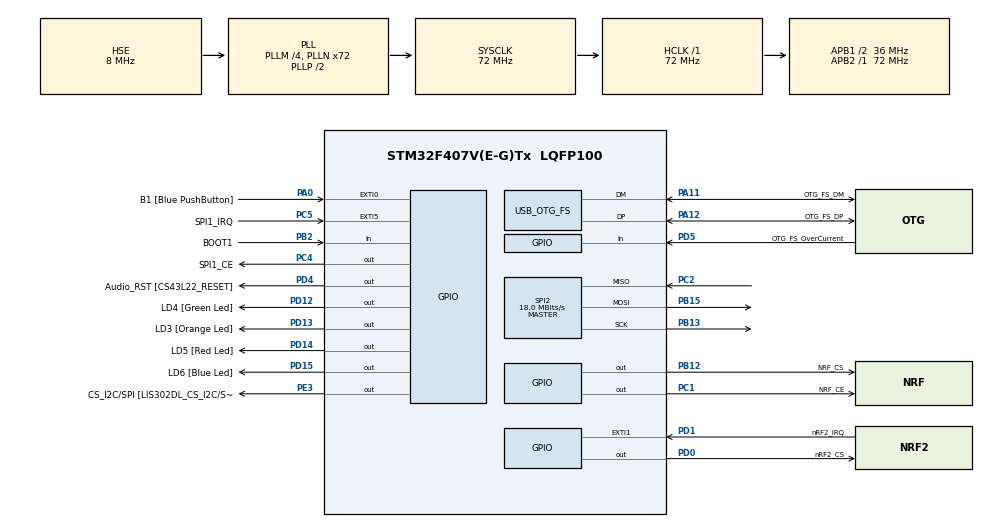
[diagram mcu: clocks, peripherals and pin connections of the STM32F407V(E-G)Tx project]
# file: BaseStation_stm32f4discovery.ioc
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FREERTOS.Tasks01=communicationTa,0,1024,communicationTask,As weak,NULL,Dynamic,NULL,NULL
Mcu.Family=STM32F4
Mcu.Name=STM32F407V(E-G)Tx
Mcu.Package=LQFP100
NVIC.OTG_FS_IRQn=true\:5\:0\:false\:false\:true\:true\:true\:true
NVIC.PriorityGroup=NVIC_PRIORITYGROUP_4
NVIC.TIM8_TRG_COM_TIM14_IRQn=true\:0\:0\:false\:false\:true\:false\:true\:true
NVIC.TimeBase=TIM8_TRG_COM_TIM14_IRQn
NVIC.TimeBaseIP=TIM14
PA0-WKUP.GPIO_Label=B1 [Blue PushButton]
PA0-WKUP.GPIO_ModeDefaultEXTI=GPIO_MODE_EVT_RISING
PA0-WKUP.GPIO_PuPd=GPIO_NOPULL
PA0-WKUP.Signal=GPXTI0
PA10.GPIO_Label=OTG_FS_ID
PA10.GPIO_Mode=GPIO_MODE_AF_PP
PA10.GPIO_PuPd=GPIO_NOPULL
PA10.GPIO_Speed=GPIO_SPEED_FREQ_LOW
PA10.Signal=USB_OTG_FS_ID
PA11.GPIO_Label=OTG_FS_DM
PA11.GPIO_Mode=GPIO_MODE_AF_PP
PA11.GPIO_PuPd=GPIO_NOPULL
PA11.GPIO_Speed=GPIO_SPEED_FREQ_LOW
PA11.Mode=Device_Only
PA11.Signal=USB_OTG_FS_DM
PA12.GPIO_Label=OTG_FS_DP
PA12.GPIO_Mode=GPIO_MODE_AF_PP
PA12.GPIO_PuPd=GPIO_NOPULL
PA12.GPIO_Speed=GPIO_SPEED_FREQ_LOW
PA12.Mode=Device_Only
PA12.Signal=USB_OTG_FS_DP
PA13.GPIO_Label=SWDIO
PA13.Signal=SYS_JTMS-SWDIO
PA14.GPIO_Label=SWCLK
PA14.Signal=SYS_JTCK-SWCLK
PA9.GPIO_Label=VBUS_FS
PA9.GPIO_Mode=GPIO_MODE_INPUT
PA9.GPIO_PuPd=GPIO_NOPULL
PA9.Signal=USB_OTG_FS_VBUS
PB12.GPIO_Label=NRF_CS
PB12.Signal=GPIO_Output
PB13.Mode=Full_Duplex_Master
PB13.Signal=SPI2_SCK
PB15.Mode=Full_Duplex_Master
PB15.Signal=SPI2_MOSI
PB2.GPIO_Label=BOOT1
PB2.GPIO_Mode=GPIO_MODE_INPUT
PB2.GPIO_PuPd=GPIO_NOPULL
PB2.Signal=GPIO_Input
PB3.GPIO_Label=SWO
PB3.Signal=SYS_JTDO-SWO
PC1.GPIO_Label=NRF_CE
PC1.Signal=GPIO_Output
PC14-OSC32_IN.Signal=RCC_OSC32_IN
PC15-OSC32_OUT.GPIO_Label=PC15-OSC32_OUT
PC15-OSC32_OUT.Signal=RCC_OSC32_OUT
PC2.Mode=Full_Duplex_Master
PC2.Signal=SPI2_MISO
PC4.GPIO_Label=SPI1_CE
PC4.Signal=GPIO_Output
PC5.GPIO_Label=SPI1_IRQ
PC5.Signal=GPXTI5
PD0.GPIO_Label=nRF2_CS
PD0.Signal=GPIO_Output
PD1.GPIO_Label=nRF2_IRQ
PD1.Signal=GPXTI1
PD12.GPIO_Label=LD4 [Green Led]
PD12.GPIO_PuPd=GPIO_NOPULL
PD12.GPIO_Speed=GPIO_SPEED_FREQ_LOW
PD12.Signal=GPIO_Output
PD13.GPIO_Label=LD3 [Orange Led]
PD13.GPIO_PuPd=GPIO_NOPULL
PD13.GPIO_Speed=GPIO_SPEED_FREQ_LOW
PD13.Signal=GPIO_Output
PD14.GPIO_Label=LD5 [Red Led]
PD14.GPIO_PuPd=GPIO_NOPULL
PD14.GPIO_Speed=GPIO_SPEED_FREQ_LOW
PD14.Signal=GPIO_Output
PD15.GPIO_Label=LD6 [Blue Led]
PD15.GPIO_PuPd=GPIO_NOPULL
PD15.GPIO_Speed=GPIO_SPEED_FREQ_LOW
PD15.Signal=GPIO_Output
PD4.GPIO_Label=Audio_RST [CS43L22_RESET]
PD4.GPIO_PuPd=GPIO_NOPULL
PD4.GPIO_Speed=GPIO_SPEED_FREQ_LOW
PD4.Signal=GPIO_Output
PD5.GPIO_Label=OTG_FS_OverCurrent
PD5.GPIO_Mode=GPIO_MODE_INPUT
PD5.GPIO_PuPd=GPIO_NOPULL
PD5.Signal=GPIO_Input
PE3.GPIO_Label=CS_I2C/SPI [LIS302DL_CS_I2C/SPI]
PE3.GPIO_PuPd=GPIO_NOPULL
PE3.GPIO_Speed=GPIO_SPEED_FREQ_LOW
PE3.Signal=GPIO_Output
PH0-OSC_IN.GPIO_Label=PH0-OSC_IN
PH0-OSC_IN.Mode=HSE-External-Oscillator
PH0-OSC_IN.Signal=RCC_OSC_IN
PH1-OSC_OUT.GPIO_Label=PH1-OSC_OUT
PH1-OSC_OUT.Mode=HSE-External-Oscillator
PH1-OSC_OUT.Signal=RCC_OSC_OUT
ProjectManager.HeapSize=0x200
ProjectManager.StackSize=0x400
ProjectManager.TargetToolchain=SW4STM32
RCC.48MHZClocksFreq_Value=48000000
RCC.AHBFreq_Value=72000000
RCC.APB1CLKDivider=RCC_HCLK_DIV2
RCC.APB1Freq_Value=36000000
RCC.APB1TimFreq_Value=72000000
RCC.APB2Freq_Value=72000000
RCC.APB2TimFreq_Value=72000000
RCC.CortexFreq_Value=72000000
RCC.HCLKFreq_Value=72000000
RCC.HSE_VALUE=8000000
RCC.HSI_VALUE=16000000
RCC.LSE_VALUE=32768
RCC.PLLM=4
RCC.PLLN=72
RCC.PLLQ=3
RCC.SYSCLKFreq_VALUE=72000000
RCC.SYSCLKSource=RCC_SYSCLKSOURCE_PLLCLK
RCC.VCOOutputFreq_Value=144000000
SPI2.CalculateBaudRate=18.0 MBits/s
SPI2.Direction=SPI_DIRECTION_2LINES
SPI2.Mode=SPI_MODE_MASTER
SPI2.VirtualType=VM_MASTER
USB_DEVICE.CLASS_NAME-CDC_FS=CDC
USB_DEVICE.CLASS_NAME_FS=CDC
USB_DEVICE.USBD_HandleTypeDef-CDC_FS=hUsbDeviceFS
USB_DEVICE.VirtualMode-CDC_FS=Cdc
USB_DEVICE.VirtualModeFS=Cdc_FS
USB_DEVICE.hUsbDevice-CDC_FS=hDeviceDuSmolt
USB_OTG_FS.VirtualMode=Device_Only
VP_FREERTOS_VS_CMSIS_V1.Mode=CMSIS_V1
VP_SYS_VS_tim14.Mode=TIM14
VP_USB_DEVICE_VS_USB_DEVICE_CDC_FS.Mode=CDC_FS
board=STM32F4DISCOVERY

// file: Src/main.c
/* USER CODE BEGIN Header */
/**
  ******************************************************************************
  * @file           : main.c
  * @brief          : Main program body
  ******************************************************************************
  * @attention
  *
  * <h2><center>&copy; Copyright (c) 2019 STMicroelectronics.
  * All rights reserved.</center></h2>
  *
  * This software component is licensed by ST under Ultimate Liberty license
  * SLA0044, the "License"; You may not use this file except in compliance with
  * the License. You may obtain a copy of the License at:
  *                             www.st.com/SLA0044
  *
  ******************************************************************************
  */
/* USER CODE END Header */

#include "main.h"
#include "cmsis_os.h"
#include "spi.h"
#include "usb_device.h"
#include "gpio.h"

/* USER CODE BEGIN PV */
/* Private variables ---------------------------------------------------------*/

/* USER CODE END PV */

void SystemClock_Config(void);
void MX_FREERTOS_Init(void);
/* USER CODE BEGIN PFP */
/* Private function prototypes -----------------------------------------------*/

/* USER CODE END PFP */

int main(void)
{

  /* MCU Configuration--------------------------------------------------------*/

  /* Reset of all peripherals, Initializes the Flash interface and the Systick. */
  HAL_Init();

  /* Configure the system clock */
  SystemClock_Config();

  /* Initialize all configured peripherals */
  MX_GPIO_Init();
  MX_SPI2_Init();
  /* USER CODE BEGIN 2 */

  //communicationTask();

  /* USER CODE END 2 */

  /* Call init function for freertos objects (in freertos.c) */
  MX_FREERTOS_Init();

  /* Start scheduler */
  osKernelStart();

  /* We should never get here as control is now taken by the scheduler */

  /* Infinite loop */
  while (1)
  {

  }
}

void SystemClock_Config(void)
{
  RCC_OscInitTypeDef RCC_OscInitStruct = {0};
  RCC_ClkInitTypeDef RCC_ClkInitStruct = {0};

  /** Configure the main internal regulator output voltage
  */
  __HAL_RCC_PWR_CLK_ENABLE();
  __HAL_PWR_VOLTAGESCALING_CONFIG(PWR_REGULATOR_VOLTAGE_SCALE1);
  /** Initializes the CPU, AHB and APB busses clocks
  */
  RCC_OscInitStruct.OscillatorType = RCC_OSCILLATORTYPE_HSE;
  RCC_OscInitStruct.HSEState = RCC_HSE_ON;
  RCC_OscInitStruct.PLL.PLLState = RCC_PLL_ON;
  RCC_OscInitStruct.PLL.PLLSource = RCC_PLLSOURCE_HSE;
  RCC_OscInitStruct.PLL.PLLM = 4;
  RCC_OscInitStruct.PLL.PLLN = 72;
  RCC_OscInitStruct.PLL.PLLP = RCC_PLLP_DIV2;
  RCC_OscInitStruct.PLL.PLLQ = 3;
  if (HAL_RCC_OscConfig(&RCC_OscInitStruct) != HAL_OK)
  {
    Error_Handler();
  }
  /** Initializes the CPU, AHB and APB busses clocks
  */
  RCC_ClkInitStruct.ClockType = RCC_CLOCKTYPE_HCLK|RCC_CLOCKTYPE_SYSCLK
                              |RCC_CLOCKTYPE_PCLK1|RCC_CLOCKTYPE_PCLK2;
  RCC_ClkInitStruct.SYSCLKSource = RCC_SYSCLKSOURCE_PLLCLK;
  RCC_ClkInitStruct.AHBCLKDivider = RCC_SYSCLK_DIV1;
  RCC_ClkInitStruct.APB1CLKDivider = RCC_HCLK_DIV2;
  RCC_ClkInitStruct.APB2CLKDivider = RCC_HCLK_DIV1;

  if (HAL_RCC_ClockConfig(&RCC_ClkInitStruct, FLASH_LATENCY_2) != HAL_OK)
  {
    Error_Handler();
  }
}

void HAL_TIM_PeriodElapsedCallback(TIM_HandleTypeDef *htim)
{
  if (htim->Instance == TIM14) {
    HAL_IncTick();
  }
}

void Error_Handler(void)
{
}

/************************ (C) COPYRIGHT STMicroelectronics *****END OF FILE****/

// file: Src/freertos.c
/* USER CODE BEGIN Header */
/**
  ******************************************************************************
  * File Name          : freertos.c
  * Description        : Code for freertos applications
  ******************************************************************************
  * @attention
  *
  * <h2><center>&copy; Copyright (c) 2019 STMicroelectronics.
  * All rights reserved.</center></h2>
  *
  * This software component is licensed by ST under Ultimate Liberty license
  * SLA0044, the "License"; You may not use this file except in compliance with
  * the License. You may obtain a copy of the License at:
  *                             www.st.com/SLA0044
  *
  ******************************************************************************
  */
/* USER CODE END Header */

#include "FreeRTOS.h"
#include "task.h"
#include "main.h"
#include "cmsis_os.h"

/* USER CODE BEGIN Includes */
#include "../../../Src/robocup/nrfDriver/nrfDriver.h"
#include "usbd_cdc_if.h"

#include "robocup/cobs/cobs.h"
#include "robocup/hermes/hermes.h"
#include "robocup/hermes/communicationTask.h"
#include "robocup/usb/serialUsb.h"
/* USER CODE END Includes */

osThreadId communicationTaHandle;

void communicationTask(void const * argument);

extern void MX_USB_DEVICE_Init(void);
void MX_FREERTOS_Init(void); /* (MISRA C 2004 rule 8.1) */

/* GetIdleTaskMemory prototype (linked to static allocation support) */
void vApplicationGetIdleTaskMemory( StaticTask_t **ppxIdleTaskTCBBuffer, StackType_t **ppxIdleTaskStackBuffer, uint32_t *pulIdleTaskStackSize );

/* USER CODE BEGIN GET_IDLE_TASK_MEMORY */
static StaticTask_t xIdleTaskTCBBuffer;
static StackType_t xIdleStack[configMINIMAL_STACK_SIZE];

void vApplicationGetIdleTaskMemory( StaticTask_t **ppxIdleTaskTCBBuffer, StackType_t **ppxIdleTaskStackBuffer, uint32_t *pulIdleTaskStackSize )
{
  *ppxIdleTaskTCBBuffer = &xIdleTaskTCBBuffer;
  *ppxIdleTaskStackBuffer = &xIdleStack[0];
  *pulIdleTaskStackSize = configMINIMAL_STACK_SIZE;
  /* place for user code */
}
/* USER CODE END GET_IDLE_TASK_MEMORY */

void MX_FREERTOS_Init(void) {

  /* Create the thread(s) */
  /* definition and creation of communicationTa */
  osThreadDef(communicationTa, communicationTask, osPriorityNormal, 0, 1024);
  communicationTaHandle = osThreadCreate(osThread(communicationTa), NULL);

}

__weak void communicationTask(void const * argument)
{

  /* init code for USB_DEVICE */
  MX_USB_DEVICE_Init();

  for(;;)
  {
    osDelay(1);
  }
}

/************************ (C) COPYRIGHT STMicroelectronics *****END OF FILE****/
